AUTOSAR XML (schema 00052)
package /apd/AdaptiveApplicationSwComponentTypes
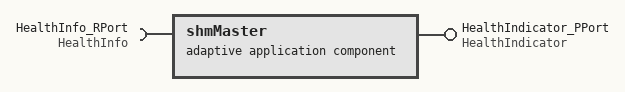
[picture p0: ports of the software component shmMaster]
  adaptive application sw component type shmMaster
    require port HealthInfo_RPort: required-interface=HealthInfo
    provide port HealthIndicator_PPort: provided-interface=HealthIndicator
package /apd/Executables
  executable shmMaster: category=APPLICATION_LEVEL, minimum-timer-granularity=1000
    root sw component prototype shmMaster: application-type=shmMaster
